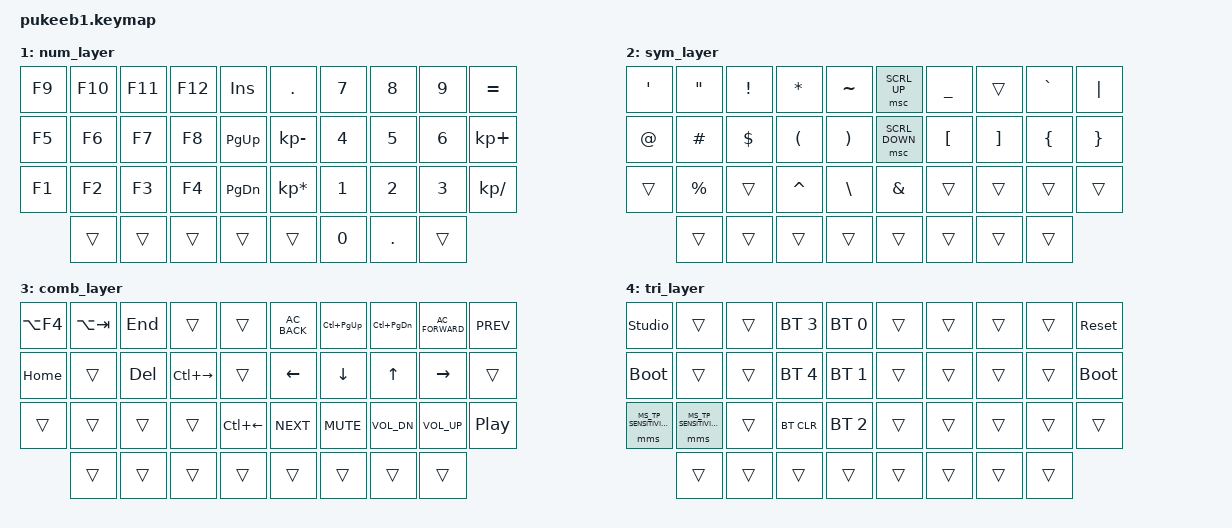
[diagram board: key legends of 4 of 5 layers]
// Copyright (c) 2022 The ZMK Contributors
// SPDX-License-Identifier: MIT

#include <behaviors.dtsi>
#include <dt-bindings/zmk/keys.h>
#include <dt-bindings/zmk/mouse.h>
#include <dt-bindings/zmk/bt.h>

// Home row mods macro
#define HRML(k1,k2,k3,k4) &ht LALT k1  &ht LSHFT k2  &ht LGUI k3  &ht LCTRL k4
#define HRMR(k1,k2,k3,k4) &ht RCTRL k1  &ht RGUI k2  &ht RSHFT k3  &ht RALT k4
#define LCS(keycode) APPLY_MODS(MOD_LCTL | MOD_LSFT, keycode)


#include <behaviors/mouse_setting.dtsi>
#include <dt-bindings/zmk/mouse_settings.h>
#define U_MSS_TP_S_I &mms MS_TP_SENSITIVITY_INCR
#define U_MSS_TP_S_D &mms MS_TP_SENSITIVITY_DECR

/ {
    behaviors {
        ht: hold_tap {
            display-name = "Hold Tap";
            label = "hold_tap";
            compatible = "zmk,behavior-hold-tap";
            #binding-cells = <2>;
            flavor = "balanced";
            tapping-term-ms = <220>;
            quick-tap-ms = <200>;
            // global-quick-tap;
            bindings = <&kp>, <&kp>;
        };
        lt: layer_tap {
            display-name = "Layer Tap";
            compatible = "zmk,behavior-hold-tap";
            label = "LAYER_TAP";
            #binding-cells = <2>;
            // flavor = "balanced";
            tapping-term-ms = <200>;
            quick-tap-ms = <200>;
            // global-quick-tap;
            bindings = <&mo>, <&kp>;
        };
    };

    combos {
        compatible = "zmk,combos";
        combo_tab {
            timeout-ms = <50>;
            key-positions = <2 3>;
            bindings = <&kp TAB>;
        };
        middle_click {
            timeout-ms = <50>;
            key-positions = <33 34>;
            bindings = <&mkp MCLK>;
        };
    };

    conditional_layers {
        compatible = "zmk,conditional-layers";
        tri_layer {
            if-layers = <2 3>;
            then-layer = <4>;
        };
    };

    keymap {
        compatible = "zmk,keymap";
        default_layer {
            bindings = <
        //╭──────────┬──────────┬──────────┬──────────┬──────────╮   ╭──────────┬──────────┬──────────┬──────────┬──────────╮
        //│  Q       │  W       │  E       │  R       │  T       │   │  Y       │  U       │  I       │  O       │  P       │
            &kp Q      &kp W      &kp E      &kp R      &kp T          &kp Y      &kp U      &kp I      &kp O      &kp P
        //├──────────┼──────────┼──────────┼──────────┼──────────┤   ├──────────┼──────────┼──────────┼──────────┼──────────┤
        //│  A       │  S       │  D       │  F       │  G       │   │  H       │  J       │  K       │  L       │ ; :      │
            HRML(A,        S,         D,         F)     &lt 3 G         &lt 3 H    HRMR(J,        K,         L,        SEMI)
        //├──────────┼──────────┼──────────┼──────────┼──────────┤   ├──────────┼──────────┼──────────┼──────────┼──────────┤
        //│  Z       │  X       │  C       │  V       │  B       │   │  N       │  M       │ , <      │ . >      │ / ?      │
            HRMR(Z,        X,        C,          V)     &kp B          &kp N      HRML(M,        COMMA,     DOT,      FSLH)
        //╰──────────┴──────────┴──────────┼──────────┼──────────┤   ├──────────┼──────────┼──────────┴──────────┴──────────╯
                    &kp K_SLEEP   &lt 1 ENTER  &lt 3 ESC  &mkp RCLK     &mkp LCLK  &lt 2 BSPC &mt LSHFT SPACE  &kp C_PLAY
        //                                 ╰──────────┴──────────╯   ╰──────────┴──────────╯
            >;
            sensor-bindings = <&inc_dec_kp C_VOL_DN C_VOL_UP &inc_dec_kp LEFT RIGHT>;
        };

        num_layer {
            bindings = <
        //╭──────────┬──────────┬──────────┬──────────┬──────────╮   ╭────────────────┬──────────┬──────────┬──────────┬─────────────╮
        //│ F9       │ F10      │ F11      │ F12      │ INSERT   │   │ .              │ 7        │ 8        │ 9        │  =          │
            &kp F9     &kp F10    &kp F11    &kp F12    &kp INS        &kp DOT         &kp N7     &kp N8     &kp N9    &kp EQUAL
        //├──────────┼──────────┼──────────┼──────────┼──────────┤   ├────────────────┼──────────┼──────────┼──────────┼─────────────┤
        //│ F5       │ F6       │  F7      │  F8      │ PAGE UP  │   │ -              │ 4        │ 5        │ 6        │  +          │
            &kp F5     &kp F6      &kp F7     &kp F8    &kp PG_UP      &kp KP_MINUS     &kp N4     &kp N5    &kp N6      &kp KP_PLUS
        //├──────────┼──────────┼──────────┼──────────┼──────────┤   ├────────────────┼──────────┼──────────┼──────────┼─────────────┤
        //│ F1       │  F2      │  F3       │  F4     │ PAGE DN  │   │ *              │ 1        │ 2        │ 3        │ /           │
           &kp F1     &kp F2     &kp F3     &kp F4     &kp PG_DN       &kp KP_MULTIPLY  &kp N1     &kp N2     &kp N3     &kp KP_DIVIDE
        //╰──────────┴──────────┴──────────┼──────────┼──────────┤   ├──────────┼──────────┼──────────┴──────────┴──────────╯
                        &trans     &trans    &trans     &trans           &trans &kp N0     &kp DOT       &trans
        //                                 ╰──────────┴──────────╯   ╰──────────┴──────────╯
            >;
            sensor-bindings = <&inc_dec_kp C_VOL_DN C_VOL_UP &inc_dec_kp LEFT RIGHT>;
        };

        sym_layer {
            bindings = <
        //╭──────────┬──────────┬──────────┬──────────┬──────────╮   ╭────────────┬──────────┬──────────┬──────────┬──────────╮
        //│  '       │  "       │  !       │  *       │  ~       │   │ scroll up  │  _       │          │  `       │  |       │
            &kp SQT     &kp DQT   &kp EXCL   &kp STAR   &kp TILDE      &msc SCRL_UP    &kp UNDER  &trans     &kp GRAVE  &kp PIPE
        //├──────────┼──────────┼──────────┼──────────┼──────────┤   ├────────────┼──────────┼──────────┼──────────┼──────────┤
        //│  @       │  #       │  $       │  (       │  )       │   │ scroll down│  [       │  ]       │ {        │  }       │
            &kp AT     &kp HASH   &kp DLLR   &kp LPAR   &kp RPAR       &msc SCRL_DOWN    &kp LBKT   &kp RBKT  &kp LBRC   &kp RBRC
        //├──────────┼──────────┼──────────┼──────────┼──────────┤   ├────────────┼──────────┼──────────┼──────────┼──────────┤
        //│          │  %       │          │ ^        │  \       │   │  &         │          │          │          │          │
            &trans     &kp PRCNT  &trans     &kp CARET  &kp BSLH       &kp AMPS     &trans     &trans    &trans     &trans
        //╰──────────┴──────────┴──────────┼──────────┼──────────┤   ├────────────┼──────────┼──────────┴──────────┴──────────╯
                        &trans     &trans    &trans     &trans         &trans       &trans     &trans     &trans
        //                                 ╰──────────┴──────────╯   ╰────────────┴──────────╯
            >;
            sensor-bindings = <&inc_dec_kp C_VOL_DN C_VOL_UP &inc_dec_kp LEFT RIGHT>;
        };

        comb_layer {
            bindings = <
        //╭──────────┬────────────┬───────────┬──────────────┬─────────────╮   ╭──────────────┬───────────────┬─────────────┬─────────────────┬──────────╮
        //│ LALT+F4  │ LALT+Tab   │ END       │              │             │   │ Backward     │ C-PgUp        │ C-PgDn      │ Forward         │ Previous │
           &kp LA(F4)  &kp LA(TAB)  &kp END     &trans         &trans            &kp C_AC_BACK  &kp LC(PG_UP)   &kp LC(PG_DN) &kp C_AC_FORWARD  &kp C_PREV
        //├──────────┼────────────┼───────────┼──────────────┼─────────────┤   ├──────────────┼───────────────┼─────────────┼─────────────────┼──────────┤
        //│HOME      │            │ DELETE    │ C-Right      │             │   │ Left         │ Down          │ Up          │ Right           │          │
           &kp HOME    &trans       &kp DEL    &kp LC(RIGHT)  &trans             &kp LEFT       &kp DOWN        &kp UP        &kp RIGHT         &trans
        //├──────────┼────────────┼───────────┼──────────────┼─────────────┤   ├──────────────┼───────────────┼─────────────┼─────────────────┼──────────┤
        //│          │            │           │              │ C-Left      │   │ Next         │ Mute          │ Vol -       │ Vol +           │ Play     │
            &trans     &trans       &trans      &trans         &kp LC(LEFT)      &kp C_NEXT     &kp C_MUTE      &kp C_VOL_DN  &kp C_VOL_UP      &kp C_PP
        //╰──────────┴────────────┴───────────┼──────────────┼─────────────┤   ├──────────────┼───────────────┼─────────────┴─────────────────┴──────────╯
                        &trans     &trans    &trans     &trans         &trans       &trans     &trans     &trans
        //                                    ╰──────────────┴─────────────╯   ╰──────────────┴───────────────╯
            >;
            sensor-bindings = <&inc_dec_kp C_VOL_DN C_VOL_UP &inc_dec_kp LEFT RIGHT>;
        };

        tri_layer {
            bindings = <
        //╭──────────────┬──────────────┬──────────┬─────────────┬────────────╮   ╭──────────┬──────────┬──────────┬──────────┬──────────╮
        //│ ZMK STUDIO   │              │          │ PROFILE 3   │PROFILE 0   │   │          │          │          │          │  RESET   │
           &studio_unlock   &trans        &trans     &bt BT_SEL 3 &bt BT_SEL 0      &trans     &trans     &trans     &trans    &sys_reset
        //├──────────────┼──────────────┼──────────┼─────────────┼────────────┤   ├──────────┼──────────┼──────────┼──────────┼──────────┤
        //│BOOTLOADER    │              │          │ PROFILE 4   │PROFILE 1   │   │          │          │          │          │BOOTLOADER│
           &bootloader     &trans          &trans    &bt BT_SEL 4 &bt BT_SEL 1      &trans     &trans     &trans     &trans    &bootloader
        //├──────────────┼──────────────┼──────────┼─────────────┼────────────┤   ├──────────┼──────────┼──────────┼──────────┼──────────┤
        //│              │              │          │ CLEAR BT    │PROFILE 2   │   │          │          │          │          │          │
           U_MSS_TP_S_D    U_MSS_TP_S_I     &trans   &bt BT_CLR   &bt BT_SEL 2      &trans     &trans     &trans     &trans    &trans
        //╰──────────────┴──────────────┴──────────┼─────────────┼────────────┤   ├──────────┼──────────┼──────────┴──────────┴──────────╯
                       &trans     &trans    &trans     &trans             &trans     &trans     &trans     &trans
        //                                 ╰─────────────┴──────────╯   ╰──────────┴──────────╯
            >;
            sensor-bindings = <&inc_dec_kp C_VOL_DN C_VOL_UP &inc_dec_kp LEFT RIGHT>;
        };
    };
};
